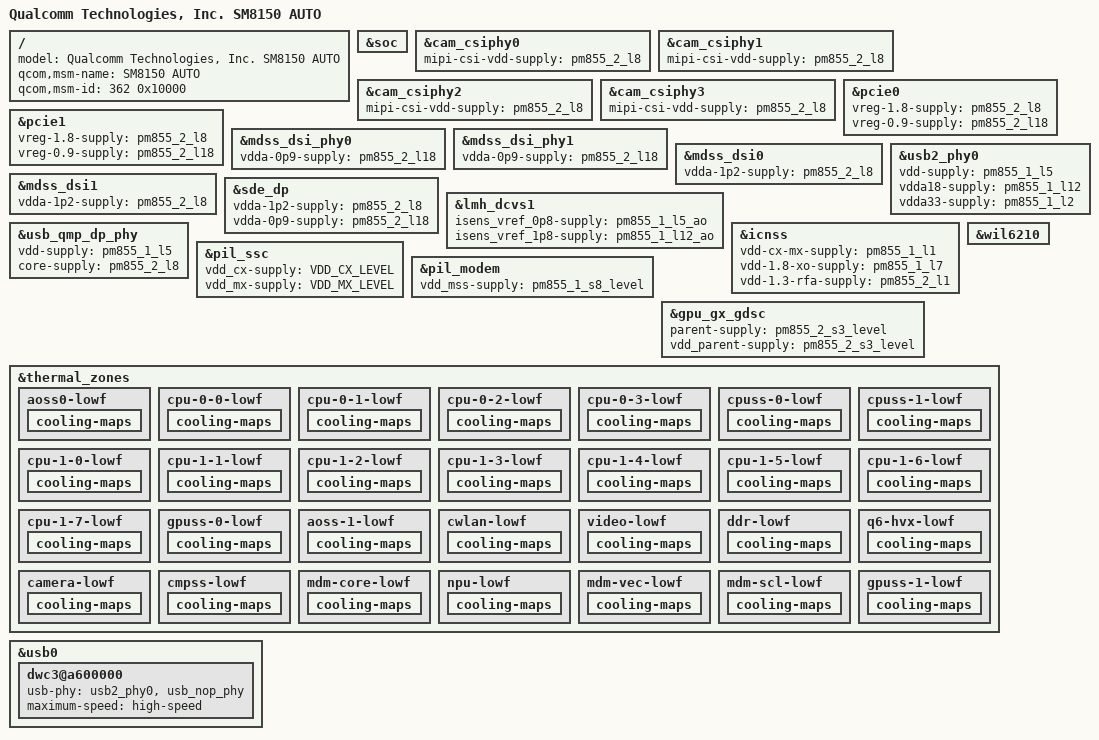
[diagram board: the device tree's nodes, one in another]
/* Copyright (c) 2018, The Linux Foundation. All rights reserved.
 *
 * This program is free software; you can redistribute it and/or modify
 * it under the terms of the GNU General Public License version 2 and
 * only version 2 as published by the Free Software Foundation.
 *
 * This program is distributed in the hope that it will be useful,
 * but WITHOUT ANY WARRANTY; without even the implied warranty of
 * MERCHANTABILITY or FITNESS FOR A PARTICULAR PURPOSE.  See the
 * GNU General Public License for more details.
 */

#include "sm8150.dtsi"

/ {
	model = "Qualcomm Technologies, Inc. SM8150 AUTO";
	qcom,msm-name = "SM8150 AUTO";
	qcom,msm-id = <362 0x10000>;
};

/* Remove regulator nodes specific to SM8150 */
&soc {
	/delete-node/ regulator-pm855-s4;
	/delete-node/ rpmh-regulator-msslvl;
	/delete-node/ rpmh-regulator-smpa2;
	/delete-node/ rpmh-regulator-ebilvl;
	/delete-node/ rpmh-regulator-smpa5;
	/delete-node/ rpmh-regulator-smpa6;
	/delete-node/ rpmh-regulator-ldoa1;
	/delete-node/ rpmh-regulator-ldoa2;
	/delete-node/ rpmh-regulator-ldoa3;
	/delete-node/ rpmh-regulator-lmxlvl;
	/delete-node/ rpmh-regulator-ldoa5;
	/delete-node/ rpmh-regulator-ldoa6;
	/delete-node/ rpmh-regulator-ldoa7;
	/delete-node/ rpmh-regulator-lcxlvl;
	/delete-node/ rpmh-regulator-ldoa9;
	/delete-node/ rpmh-regulator-ldoa10;
	/delete-node/ rpmh-regulator-ldoa11;
	/delete-node/ rpmh-regulator-ldoa12;
	/delete-node/ rpmh-regulator-ldoa13;
	/delete-node/ rpmh-regulator-ldoa14;
	/delete-node/ rpmh-regulator-ldoa15;
	/delete-node/ rpmh-regulator-ldoa16;
	/delete-node/ rpmh-regulator-ldoa17;
	/delete-node/ rpmh-regulator-smpc1;
	/delete-node/ rpmh-regulator-gfxlvl;
	/delete-node/ rpmh-regulator-mxlvl;
	/delete-node/ rpmh-regulator-mmcxlvl;
	/delete-node/ rpmh-regulator-cxlvl;
	/delete-node/ rpmh-regulator-smpc8;
	/delete-node/ rpmh-regulator-ldoc1;
	/delete-node/ rpmh-regulator-ldoc2;
	/delete-node/ rpmh-regulator-ldoc3;
	/delete-node/ rpmh-regulator-ldoc4;
	/delete-node/ rpmh-regulator-ldoc5;
	/delete-node/ rpmh-regulator-ldoc6;
	/delete-node/ rpmh-regulator-ldoc7;
	/delete-node/ rpmh-regulator-ldoc8;
	/delete-node/ rpmh-regulator-ldoc9;
	/delete-node/ rpmh-regulator-ldoc10;
	/delete-node/ rpmh-regulator-ldoc11;
	/delete-node/ rpmh-regulator-bobc1;
	/delete-node/ rpmh-regulator-smpf2;
	/delete-node/ rpmh-regulator-ldof2;
	/delete-node/ rpmh-regulator-ldof5;
	/delete-node/ rpmh-regulator-ldof6;
};

/* Add regulator nodes specific to SM8150 Auto */
#include "sm8150-auto-regulator.dtsi"

&cam_csiphy0 {
	mipi-csi-vdd-supply = <&pm855_2_l8>;
};

&cam_csiphy1 {
	mipi-csi-vdd-supply = <&pm855_2_l8>;
};

&cam_csiphy2 {
	mipi-csi-vdd-supply = <&pm855_2_l8>;
};

&cam_csiphy3 {
	mipi-csi-vdd-supply = <&pm855_2_l8>;
};

&pcie0 {
	vreg-1.8-supply = <&pm855_2_l8>;
	vreg-0.9-supply = <&pm855_2_l18>;
};

&pcie1 {
	vreg-1.8-supply = <&pm855_2_l8>;
	vreg-0.9-supply = <&pm855_2_l18>;
};

&mdss_dsi_phy0 {
		vdda-0p9-supply = <&pm855_2_l18>;
};

&mdss_dsi_phy1 {
		vdda-0p9-supply = <&pm855_2_l18>;
};

&mdss_dsi0 {
	vdda-1p2-supply = <&pm855_2_l8>;
};

&mdss_dsi1 {
	vdda-1p2-supply = <&pm855_2_l8>;
};

&sde_dp {
	vdda-1p2-supply = <&pm855_2_l8>;
	vdda-0p9-supply = <&pm855_2_l18>;
};

&lmh_dcvs1 {
	isens_vref_0p8-supply = <&pm855_1_l5_ao>;
	isens_vref_1p8-supply = <&pm855_1_l12_ao>;
};

&usb2_phy0 {
	vdd-supply = <&pm855_1_l5>;
	vdda18-supply = <&pm855_1_l12>;
	vdda33-supply = <&pm855_1_l2>;
};

&usb_qmp_dp_phy {
	vdd-supply = <&pm855_1_l5>;
	core-supply = <&pm855_2_l8>;
};

&icnss {
	vdd-cx-mx-supply = <&pm855_1_l1>;
	vdd-1.8-xo-supply = <&pm855_1_l7>;
	vdd-1.3-rfa-supply = <&pm855_2_l1>;
	/delete-property/ vdd-3.3-ch0-supply;
};

&pil_ssc {
	vdd_cx-supply = <&VDD_CX_LEVEL>;
	vdd_mx-supply = <&VDD_MX_LEVEL>;
};

&pil_modem {
	vdd_mss-supply = <&pm855_1_s8_level>;
};

&wil6210 {
	/delete-property/ vddio-supply;
};

&gpu_gx_gdsc {
	parent-supply = <&pm855_2_s3_level>;
	vdd_parent-supply = <&pm855_2_s3_level>;
};

&thermal_zones {
	aoss0-lowf {
		cooling-maps {
			/delete-node/ mmcx_vdd_cdev;
		};
	};
	cpu-0-0-lowf {
		cooling-maps {
			/delete-node/ mmcx_vdd_cdev;
		};
	};
	cpu-0-1-lowf {
		cooling-maps {
			/delete-node/ mmcx_vdd_cdev;
		};
	};
	cpu-0-2-lowf {
		cooling-maps {
			/delete-node/ mmcx_vdd_cdev;
		};
	};
	cpu-0-3-lowf {
		cooling-maps {
			/delete-node/ mmcx_vdd_cdev;
		};
	};
	cpuss-0-lowf {
		cooling-maps {
			/delete-node/ mmcx_vdd_cdev;
		};
	};
	cpuss-1-lowf {
		cooling-maps {
			/delete-node/ mmcx_vdd_cdev;
		};
	};
	cpu-1-0-lowf {
		cooling-maps {
			/delete-node/ mmcx_vdd_cdev;
		};
	};
	cpu-1-1-lowf {
		cooling-maps {
			/delete-node/ mmcx_vdd_cdev;
		};
	};
	cpu-1-2-lowf {
		cooling-maps {
			/delete-node/ mmcx_vdd_cdev;
		};
	};
	cpu-1-3-lowf {
		cooling-maps {
			/delete-node/ mmcx_vdd_cdev;
		};
	};
	cpu-1-4-lowf {
		cooling-maps {
			/delete-node/ mmcx_vdd_cdev;
		};
	};
	cpu-1-5-lowf {
		cooling-maps {
			/delete-node/ mmcx_vdd_cdev;
		};
	};
	cpu-1-6-lowf {
		cooling-maps {
			/delete-node/ mmcx_vdd_cdev;
		};
	};
	cpu-1-7-lowf {
		cooling-maps {
			/delete-node/ mmcx_vdd_cdev;
		};
	};
	gpuss-0-lowf {
		cooling-maps {
			/delete-node/ mmcx_vdd_cdev;
		};
	};
	aoss-1-lowf {
		cooling-maps {
			/delete-node/ mmcx_vdd_cdev;
		};
	};
	cwlan-lowf {
		cooling-maps {
			/delete-node/ mmcx_vdd_cdev;
		};
	};
	video-lowf {
		cooling-maps {
			/delete-node/ mmcx_vdd_cdev;
		};
	};
	ddr-lowf {
		cooling-maps {
			/delete-node/ mmcx_vdd_cdev;
		};
	};
	q6-hvx-lowf {
		cooling-maps {
			/delete-node/ mmcx_vdd_cdev;
		};
	};
	camera-lowf {
		cooling-maps {
			/delete-node/ mmcx_vdd_cdev;
		};
	};
	cmpss-lowf {
		cooling-maps {
			/delete-node/ mmcx_vdd_cdev;
		};
	};
	mdm-core-lowf {
		cooling-maps {
			/delete-node/ mmcx_vdd_cdev;
		};
	};
	npu-lowf {
		cooling-maps {
			/delete-node/ mmcx_vdd_cdev;
		};
	};
	mdm-vec-lowf {
		cooling-maps {
			/delete-node/ mmcx_vdd_cdev;
		};
	};
	mdm-scl-lowf {
		cooling-maps {
			/delete-node/ mmcx_vdd_cdev;
		};
	};
	gpuss-1-lowf {
		cooling-maps {
			/delete-node/ mmcx_vdd_cdev;
		};
	};
};

&usb0 {
	dwc3@a600000 {
		usb-phy = <&usb2_phy0>, <&usb_nop_phy>;
		maximum-speed = "high-speed";
	};
};
